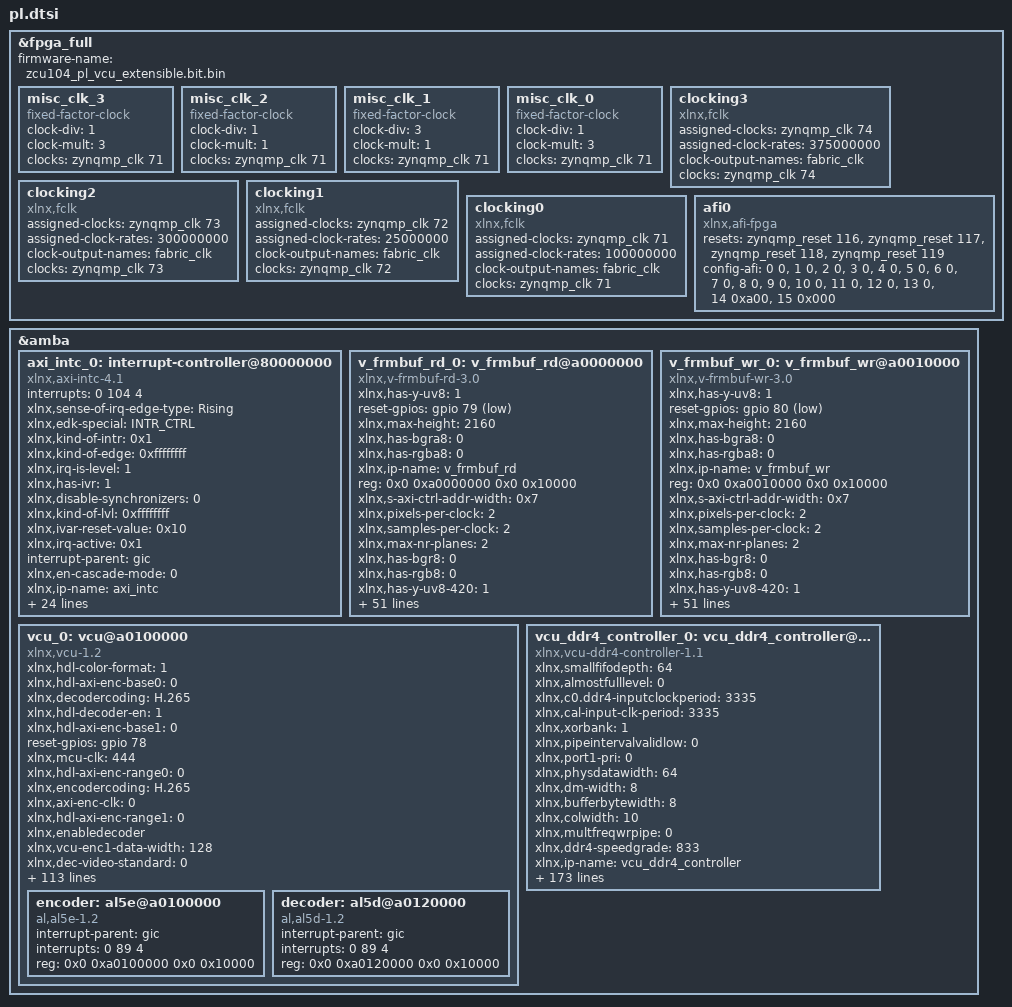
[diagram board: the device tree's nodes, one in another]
/dts-v1/;
/plugin/;
&fpga_full {
	firmware-name = "zcu104_pl_vcu_extensible.bit.bin";
	misc_clk_3: misc_clk_3 {
		clock-div = <1>;
		compatible = "fixed-factor-clock";
		clock-mult = <3>;
		clocks = <&zynqmp_clk 71>;
		#clock-cells = <0>;
	};
	misc_clk_2: misc_clk_2 {
		clock-div = <1>;
		compatible = "fixed-factor-clock";
		clock-mult = <1>;
		clocks = <&zynqmp_clk 71>;
		#clock-cells = <0>;
	};
	misc_clk_1: misc_clk_1 {
		clock-div = <3>;
		compatible = "fixed-factor-clock";
		clock-mult = <1>;
		clocks = <&zynqmp_clk 71>;
		#clock-cells = <0>;
	};
	misc_clk_0: misc_clk_0 {
		clock-div = <1>;
		compatible = "fixed-factor-clock";
		clock-mult = <3>;
		clocks = <&zynqmp_clk 71>;
		#clock-cells = <0>;
	};
	clocking3: clocking3 {
		compatible = "xlnx,fclk";
		assigned-clocks = <&zynqmp_clk 74>;
		assigned-clock-rates = <375000000>;
		#clock-cells = <0>;
		clock-output-names = "fabric_clk";
		clocks = <&zynqmp_clk 74>;
	};
	clocking2: clocking2 {
		compatible = "xlnx,fclk";
		assigned-clocks = <&zynqmp_clk 73>;
		assigned-clock-rates = <300000000>;
		#clock-cells = <0>;
		clock-output-names = "fabric_clk";
		clocks = <&zynqmp_clk 73>;
	};
	clocking1: clocking1 {
		compatible = "xlnx,fclk";
		assigned-clocks = <&zynqmp_clk 72>;
		assigned-clock-rates = <25000000>;
		#clock-cells = <0>;
		clock-output-names = "fabric_clk";
		clocks = <&zynqmp_clk 72>;
	};
	clocking0: clocking0 {
		compatible = "xlnx,fclk";
		assigned-clocks = <&zynqmp_clk 71>;
		assigned-clock-rates = <100000000>;
		#clock-cells = <0>;
		clock-output-names = "fabric_clk";
		clocks = <&zynqmp_clk 71>;
	};
	afi0: afi0 {
		compatible = "xlnx,afi-fpga";
		resets = <&zynqmp_reset 116>, <&zynqmp_reset 117>, <&zynqmp_reset 118>, <&zynqmp_reset 119>;
		config-afi = < 0 0>, <1 0>, <2 0>, <3 0>, <4 0>, <5 0>, <6 0>, <7 0>, <8 0>, <9 0>, <10 0>, <11 0>, <12 0>, <13 0>, <14 0xa00>, <15 0x000>;
	};
};

&amba {
	axi_intc_0: interrupt-controller@80000000 {
		#interrupt-cells = <2>;
		interrupts = < 0 104 4 >;
		xlnx,sense-of-irq-edge-type = "Rising";
		xlnx,edk-special = "INTR_CTRL";
		xlnx,kind-of-intr = <0x1>;
		xlnx,kind-of-edge = <0xffffffff>;
		xlnx,irq-is-level = <1>;
		xlnx,has-ivr = <1>;
		compatible = "xlnx,axi-intc-4.1" , "xlnx,xps-intc-1.00.a";
		xlnx,disable-synchronizers = <0>;
		xlnx,kind-of-lvl = <0xffffffff>;
		xlnx,ivar-reset-value = <0x10>;
		xlnx,irq-active = <0x1>;
		interrupt-parent = <&gic>;
		xlnx,en-cascade-mode = <0>;
		xlnx,ip-name = "axi_intc";
		xlnx,has-ilr = <0>;
		reg = <0x0 0x80000000 0x0 0x10000>;
		xlnx,addr-width = <0x20>;
		clocks = <&zynqmp_clk 71>;
		xlnx,s-axi-aclk-freq-mhz = <100>;
		xlnx,num-sw-intr = <0>;
		xlnx,irq-connection = <1>;
		xlnx,num-intr-inputs = <0x1>;
		xlnx,has-sie = <1>;
		xlnx,enable-async = <0>;
		xlnx,has-cie = <1>;
		xlnx,num-sync-ff = <2>;
		xlnx,edk-iptype = "PERIPHERAL";
		xlnx,mb-clk-not-connected = <1>;
		xlnx,has-ipr = <1>;
		xlnx,sense-of-irq-level-type = "Active_High";
		xlnx,cascade-master = <0>;
		xlnx,processor-clk-freq-mhz = <100>;
		xlnx,is-fast = <0x0>;
		clock-names = "s_axi_aclk";
		xlnx,has-fast = <0>;
		xlnx,ivar-rst-val = <0x10>;
		interrupt-controller;
		interrupt-names = "irq";
		xlnx,async-intr = <0xffffffff>;
		xlnx,name = "axi_intc_0";
	};
	v_frmbuf_rd_0: v_frmbuf_rd@a0000000 {
		xlnx,has-y-uv8 = <1>;
		reset-gpios = <&gpio 79 1>;
		xlnx,max-height = <2160>;
		xlnx,has-bgra8 = <0>;
		xlnx,has-rgba8 = <0>;
		xlnx,ip-name = "v_frmbuf_rd";
		reg = <0x0 0xa0000000 0x0 0x10000>;
		xlnx,s-axi-ctrl-addr-width = <0x7>;
		xlnx,pixels-per-clock = <2>;
		xlnx,samples-per-clock = <2>;
		xlnx,max-nr-planes = <2>;
		xlnx,has-bgr8 = <0>;
		xlnx,has-rgb8 = <0>;
		xlnx,has-y-uv8-420 = <1>;
		xlnx,has-yuyv8 = <0>;
		xlnx,has-y-u-v8 = <0>;
		interrupt-names = "interrupt";
		compatible = "xlnx,v-frmbuf-rd-3.0" , "xlnx,axi-frmbuf-rd-v2.2";
		xlnx,max-width = <3840>;
		xlnx,has-rgb16 = <0>;
		xlnx,vid-formats = "y8" , "y10" , "nv12" , "nv16" , "xv20" , "xv15";
		xlnx,has-bgrx8 = <0>;
		xlnx,has-rgbx8 = <0>;
		xlnx,has-rgbx10 = <0>;
		interrupt-parent = <&gic>;
		xlnx,aximm-num-outstanding = <4>;
		xlnx,has-uyvy8 = <0>;
		xlnx,use-uram = <0>;
		xlnx,has-rgbx12 = <0>;
		xlnx,aximm-burst-length = <16>;
		xlnx,aximm-addr-width = <64>;
		xlnx,video-width = <10>;
		xlnx,max-cols = <3840>;
		xlnx,has-yuv8 = <0>;
		xlnx,has-y-uv10-420 = <1>;
		xlnx,has-yuva8 = <0>;
		xlnx,has-y-uv12-420 = <0>;
		xlnx,name = "v_frmbuf_rd_0";
		interrupts = < 0 90 4 >;
		xlnx,has-y10 = <1>;
		xlnx,has-y-uv16-420 = <0>;
		xlnx,has-y12 = <0>;
		xlnx,has-alpha = <0>;
		xlnx,has-y-u-v10 = <0>;
		clocks = <&misc_clk_0>;
		xlnx,has-y16 = <0>;
		xlnx,dma-align = <16>;
		xlnx,has-y-u-v12 = <0>;
		xlnx,edk-iptype = "PERIPHERAL";
		xlnx,has-interlaced = <0>;
		xlnx,has-yuv16 = <0>;
		xlnx,has-yuvx8 = <0>;
		xlnx,is-tile-format = <0>;
		xlnx,dma-addr-width = <64>;
		clock-names = "ap_clk";
		xlnx,s-axi-ctrl-data-width = <0x20>;
		xlnx,has-y8 = <1>;
		xlnx,has-y-uv10 = <1>;
		xlnx,has-y-uv12 = <0>;
		xlnx,max-rows = <2160>;
		xlnx,has-yuvx10 = <0>;
		#dma-cells = <1>;
		xlnx,has-yuvx12 = <0>;
		xlnx,has-y-uv16 = <0>;
		xlnx,max-data-width = <10>;
		xlnx,has-y-u-v8-420 = <0>;
		xlnx,num-video-components = <3>;
		xlnx,aximm-data-width = <128>;
	};
	v_frmbuf_wr_0: v_frmbuf_wr@a0010000 {
		xlnx,has-y-uv8 = <1>;
		reset-gpios = <&gpio 80 1>;
		xlnx,max-height = <2160>;
		xlnx,has-bgra8 = <0>;
		xlnx,has-rgba8 = <0>;
		xlnx,ip-name = "v_frmbuf_wr";
		reg = <0x0 0xa0010000 0x0 0x10000>;
		xlnx,s-axi-ctrl-addr-width = <0x7>;
		xlnx,pixels-per-clock = <2>;
		xlnx,samples-per-clock = <2>;
		xlnx,max-nr-planes = <2>;
		xlnx,has-bgr8 = <0>;
		xlnx,has-rgb8 = <0>;
		xlnx,has-y-uv8-420 = <1>;
		xlnx,has-yuyv8 = <0>;
		xlnx,has-y-u-v8 = <0>;
		interrupt-names = "interrupt";
		compatible = "xlnx,v-frmbuf-wr-3.0" , "xlnx,axi-frmbuf-wr-v2.2";
		xlnx,max-width = <3840>;
		xlnx,has-rgb16 = <0>;
		xlnx,vid-formats = "y8" , "y10" , "nv12" , "nv16" , "xv20" , "xv15";
		xlnx,has-bgrx8 = <0>;
		xlnx,has-rgbx8 = <0>;
		xlnx,has-rgbx10 = <0>;
		interrupt-parent = <&gic>;
		xlnx,aximm-num-outstanding = <4>;
		xlnx,has-uyvy8 = <0>;
		xlnx,use-uram = <0>;
		xlnx,has-rgbx12 = <0>;
		xlnx,aximm-burst-length = <16>;
		xlnx,aximm-addr-width = <32>;
		xlnx,video-width = <10>;
		xlnx,max-cols = <3840>;
		xlnx,has-yuv8 = <0>;
		xlnx,has-y-uv10-420 = <1>;
		xlnx,has-yuva8 = <0>;
		xlnx,has-y-uv12-420 = <0>;
		xlnx,name = "v_frmbuf_wr_0";
		interrupts = < 0 91 4 >;
		xlnx,has-y10 = <1>;
		xlnx,has-y-uv16-420 = <0>;
		xlnx,has-y12 = <0>;
		xlnx,has-alpha = <0>;
		xlnx,has-y-u-v10 = <0>;
		clocks = <&misc_clk_0>;
		xlnx,has-y16 = <0>;
		xlnx,dma-align = <16>;
		xlnx,has-y-u-v12 = <0>;
		xlnx,edk-iptype = "PERIPHERAL";
		xlnx,has-interlaced = <0>;
		xlnx,has-yuv16 = <0>;
		xlnx,has-yuvx8 = <0>;
		xlnx,is-tile-format = <0>;
		xlnx,dma-addr-width = <32>;
		clock-names = "ap_clk";
		xlnx,s-axi-ctrl-data-width = <0x20>;
		xlnx,has-y8 = <1>;
		xlnx,has-y-uv10 = <1>;
		xlnx,has-y-uv12 = <0>;
		xlnx,max-rows = <2160>;
		xlnx,has-yuvx10 = <0>;
		#dma-cells = <1>;
		xlnx,has-yuvx12 = <0>;
		xlnx,has-y-uv16 = <0>;
		xlnx,max-data-width = <10>;
		xlnx,has-y-u-v8-420 = <0>;
		xlnx,num-video-components = <3>;
		xlnx,aximm-data-width = <128>;
	};
	vcu_0: vcu@a0100000 {
		xlnx,hdl-color-format = <1>;
		xlnx,hdl-axi-enc-base0 = <0>;
		xlnx,decodercoding = "H.265";
		xlnx,hdl-decoder-en = <1>;
		xlnx,hdl-axi-enc-base1 = <0>;
		reset-gpios = <&gpio 78 0>;
		xlnx,mcu-clk = <444>;
		xlnx,hdl-axi-enc-range0 = <0>;
		xlnx,encodercoding = "H.265";
		xlnx,axi-enc-clk = <0>;
		xlnx,hdl-axi-enc-range1 = <0>;
		xlnx,enabledecoder;
		xlnx,vcu-enc1-data-width = <128>;
		xlnx,dec-video-standard = <0>;
		xlnx,pll-bypass = <0>;
		xlnx,hdl-dec-fps = <60>;
		xlnx,encverresolution = <2160>;
		xlnx,enc-mem-bram-used = <0>;
		xlnx,ip-name = "vcu";
		#size-cells = <2>;
		reg = <0x0 0xa0140000 0x0 0x1000>, <0x0 0xa0141000 0x0 0x1000>;
		xlnx,hdl-enc-clk = <0>;
		xlnx,hdl-enc-buffer-en = <1>;
		#address-cells = <2>;
		xlnx,hdl-axi-mcu-range = <0>;
		xlnx,vcu-dec0-data-width = <128>;
		xlnx,enc-fps = <1>;
		xlnx,dec-coding-type = <1>;
		xlnx,axi-enc-range0 = <0>;
		interrupt-names = "vcu_host_interrupt";
		xlnx,hdl-vcu-test-en = <0>;
		xlnx,hdl-coding-type = <1>;
		xlnx,enc-color-format = <1>;
		xlnx,axi-enc-range1 = <0>;
		xlnx,decoderchromaformat = "4_2_2";
		compatible = "xlnx,vcu-1.2" , "xlnx,vcu";
		xlnx,vcu-axiliteapb-data-width = <32>;
		xlnx,dec-color-depth = <1>;
		xlnx,enable-encoder;
		xlnx,hdl-encoder-en = <1>;
		xlnx,decverresolution = <2160>;
		interrupt-parent = <&gic>;
		xlnx,hdl-dec-frame-size-x = <3840>;
		xlnx,hdl-color-depth = <1>;
		xlnx,hdl-dec-frame-size-y = <2160>;
		xlnx,hdl-axi-mcu-clk = <1079194419>;
		xlnx,enc-video-standard = <0>;
		ranges;
		xlnx,enc-mem-uram-used = <1710>;
		xlnx,decodernumcores = <2>;
		xlnx,no-of-streams = <8>;
		xlnx,hdl-dec-video-standard = <0>;
		xlnx,axi-mcu-clk = <330>;
		xlnx,hdl-pll-bypass = <0>;
		xlnx,enc-buffer-manual-override = <0>;
		xlnx,dec-color-format = <1>;
		xlnx,pll-clk = <0x1fca055>;
		xlnx,hdl-test-port-en = <0>;
		xlnx,hdl-axi-dec-clk = <0>;
		xlnx,hdl-mcu-clk = <444>;
		xlnx,hdl-axi-mcu-base = <0>;
		xlnx,name = "vcu_0";
		interrupts = < 0 89 4 >;
		xlnx,table-no = <1>;
		xlnx,axi-dec-clk = <0>;
		xlnx,hdl-dec-color-format = <1>;
		xlnx,hdl-ram-type = <0>;
		xlnx,hdl-pll-clk-lo = <32>;
		xlnx,enc-buffer-size-actual = <1710>;
		xlnx,vcu-dec1-data-width = <128>;
		xlnx,vcu-mcu-data-width = <32>;
		xlnx,dec-frame-size = <4>;
		xlnx,enc-buffer-size = <1520>;
		xlnx,hdl-table-no = <1>;
		xlnx,enableencoder;
		clocks = <&misc_clk_1>, <&misc_clk_2>, <&vcu_0 0>, <&vcu_0 1>, <&vcu_0 2>, <&vcu_0 3>;
		xlnx,hdl-dec-coding-type = <1>;
		xlnx,hdl-video-standard = <0>;
		xlnx,dec-fps = <3>;
		xlnx,edk-iptype = "PERIPHERAL";
		xlnx,enc-buffer-b-frame = <1>;
		xlnx,enc-clk = <0>;
		xlnx,vcu-enc0-data-width = <128>;
		xlnx,hdl-fps = <30>;
		xlnx,enc-coding-type = <1>;
		clock-names = "pll_ref" , "aclk" , "vcu_core_enc" , "vcu_mcu_enc" , "vcu_core_dec" , "vcu_mcu_dec";
		xlnx,hdl-dec-color-depth = <1>;
		xlnx,hdl-enc-buffer-motion-vec-range = <0>;
		xlnx,hdl-enc-buffer-manual-override = <0>;
		xlnx,hdl-axi-dec-range0 = <0>;
		xlnx,enable-decoder;
		xlnx,hdl-axi-dec-range1 = <0>;
		xlnx,encoderchromaformat = "4_2_2";
		xlnx,enchorresolution = <3840>;
		xlnx,axi-dec-base0 = <0>;
		xlnx,no-of-dec-streams = <1>;
		xlnx,hdl-wpp-en = <0>;
		xlnx,enc-color-depth = <1>;
		xlnx,enc-buffer-type = <0>;
		xlnx,axi-dec-base1 = <0>;
		xlnx,decodercodingtype = "INTRA_ONLY";
		xlnx,hdl-frame-size-x = <1920>;
		xlnx,axi-enc-base0 = <0>;
		xlnx,enc-buffer-motion-vec-range = <0>;
		xlnx,hdl-frame-size-y = <1080>;
		xlnx,encodercodingtype = "INTRA_ONLY";
		xlnx,enc-frame-size = <3>;
		xlnx,axi-enc-base1 = <0>;
		xlnx,core-clk = <667>;
		xlnx,hdl-num-concurrent-streams = <4>;
		xlnx,hdl-pll-clk-hi = <33>;
		xlnx,decodercolordepth = <10>;
		xlnx,encodernumcores = <4>;
		xlnx,encodercolordepth = <10>;
		xlnx,axi-mcu-base = <0>;
		xlnx,hdl-core-clk = <667>;
		xlnx,axi-dec-range0 = <0>;
		xlnx,enc-buffer-en;
		xlnx,hdl-mem-depth = <38912>;
		xlnx,axi-dec-range1 = <0>;
		xlnx,axi-mcu-range = <0>;
		xlnx,wpp-en = <0>;
		xlnx,hdl-axi-dec-base0 = <0>;
		reg-names = "vcu_slcr" , "logicore";
		#clock-cells = <1>;
		xlnx,mcu-debug = <0>;
		xlnx,hdl-num-streams = <8>;
		xlnx,hdl-max-num-cores = <4>;
		xlnx,hdl-enc-buffer-b-frame = <1>;
		xlnx,hdl-axi-enc-clk = <0>;
		xlnx,hdl-axi-dec-base1 = <0>;
		xlnx,coreclkfreq = <667>;
		xlnx,dechorresolution = <3840>;
		encoder: al5e@a0100000 {
			interrupt-parent = <&gic>;
			interrupts = < 0 89 4 >;
			compatible = "al,al5e-1.2" , "al,al5e";
			reg = <0x0 0xa0100000 0x0 0x10000>;
		};
		decoder: al5d@a0120000 {
			interrupt-parent = <&gic>;
			interrupts = < 0 89 4 >;
			compatible = "al,al5d-1.2" , "al,al5d";
			reg = <0x0 0xa0120000 0x0 0x10000>;
		};
	};
	vcu_ddr4_controller_0: vcu_ddr4_controller@4800000000 {
		xlnx,smallfifodepth = <64>;
		xlnx,almostfulllevel = <0>;
		xlnx,c0.ddr4-inputclockperiod = <3335>;
		xlnx,cal-input-clk-period = <3335>;
		xlnx,xorbank = <1>;
		xlnx,pipeintervalvalidlow = <0>;
		xlnx,port1-pri = <0>;
		xlnx,physdatawidth = <64>;
		xlnx,dm-width = <8>;
		xlnx,bufferbytewidth = <8>;
		xlnx,colwidth = <10>;
		xlnx,multfreqwrpipe = <0>;
		xlnx,ddr4-speedgrade = <833>;
		xlnx,ip-name = "vcu_ddr4_controller";
		xlnx,port3-pri = <1>;
		xlnx,pipeintervalwaithigh = <3>;
		xlnx,ddr4-custompartsfile = "no_file_loaded";
		reg = <0x00000048 0x00000000 0x0 0x80000000>;
		xlnx,usrwrpipe = <1>;
		xlnx,nbseq = <1>;
		xlnx,logenable = <0>;
		xlnx,data-buf-addr-width = <5>;
		xlnx,cust-ddr4-timeperiod = <833>;
		xlnx,hdl-port0-en = <1>;
		xlnx,dualclock = <0>;
		xlnx,ddr4-cmdgetaddr = <22>;
		xlnx,writedelay = <7>;
		xlnx,burstlength = <8>;
		xlnx,nbchipselect = <1>;
		xlnx,iaddrwidth = <22>;
		xlnx,bankwidth = <4>;
		xlnx,bufferdatawidth = <128>;
		xlnx,clkout1-divide-mmcm = <6>;
		xlnx,nbfifo = <16>;
		xlnx,odtend = <6>;
		xlnx,nrtr = <13>;
		xlnx,dram-width-hdl = <0>;
		xlnx,divclk-divide-mmcm = <3>;
		xlnx,cust-csv-memtype = "Components";
		xlnx,ddr4-cust-file-en = <0>;
		xlnx,data-width = <0>;
		xlnx,cwlatency = <14>;
		compatible = "xlnx,vcu-ddr4-controller-1.1";
		xlnx,c0-ddr4-divclk-divide = <3>;
		xlnx,nrtw = <3>;
		xlnx,cmdrep = <0>;
		xlnx,speed-bin-hdl = <1>;
		xlnx,areset = <0>;
		xlnx,c0-ddr4-clkfbout-mult = <16>;
		xlnx,nodatacmdslot = <3>;
		xlnx,hdl-port3-en = <1>;
		xlnx,dimm-value-hdl = <0>;
		xlnx,ddr4-sdrambank = <16>;
		xlnx,trfc = <260>;
		xlnx,physaddrwidth = <17>;
		xlnx,wrpipe = <1>;
		xlnx,caslatency = <15>;
		xlnx,c0.ddr4-clkout0-divide = <6>;
		xlnx,drivestrength = <0>;
		xlnx,ddr4-cmdflag = <16>;
		xlnx,rddatafifopipe = <1>;
		xlnx,resetlevel = <1>;
		xlnx,ref-clk = <300>;
		xlnx,nfaw = <6>;
		xlnx,maxpostedrefresh = <1>;
		xlnx,ddr4-cmdwait = <16>;
		xlnx,cust-csv-clkout2-freq = <300>;
		xlnx,twr = <15>;
		xlnx,coldelay = <4>;
		xlnx,writegrouping = <32>;
		xlnx,c0.ddr4-timeperiod = <938>;
		xlnx,port0-pri-idx = <1>;
		xlnx,dbgmoncntsize = <16>;
		xlnx,c0.controllertype = "ddr4_sdram";
		xlnx,combineaxiburst = <1>;
		xlnx,rowwidth = <15>;
		xlnx,port1-pri-idx = <2>;
		xlnx,port2-pri-idx = <4>;
		xlnx,enable-port0;
		xlnx,name = "vcu_ddr4_controller_0";
		xlnx,usrburstwidth = <8>;
		xlnx,tck = <938>;
		xlnx,port3-pri-idx = <5>;
		xlnx,enable-port1;
		xlnx,ddr = <4>;
		xlnx,port4-pri-idx = <3>;
		xlnx,nwtr = <7>;
		xlnx,no-of-axi-ports = <5>;
		xlnx,nbcke = <1>;
		xlnx,hdl-port1-en = <1>;
		xlnx,enable-port2;
		xlnx,cust-enable = <0>;
		xlnx,c0.ddr4-divclk-divide = <3>;
		xlnx,incrburst = <0>;
		xlnx,fastfaw = <0>;
		xlnx,enable-port3;
		xlnx,nbbank = <16>;
		xlnx,port0-pri = <0>;
		xlnx,enable-port4;
		xlnx,dqs-width = <8>;
		xlnx,c0.ddr4-clkfbout-mult = <16>;
		xlnx,trace-length = <3>;
		xlnx,clkinperiodmmcm = <3335>;
		xlnx,readgrouping = <96>;
		xlnx,port2-pri = <1>;
		xlnx,ping-pong = <1>;
		xlnx,cust-csv-datawidth = <64>;
		xlnx,nwtw = <16>;
		xlnx,multfreq = <1>;
		xlnx,memory-timeperiod = <100>;
		xlnx,dram-speed-bin = <2>;
		xlnx,ddr4-customparts = "no_file_loaded";
		clocks = <&misc_clk_3>;
		xlnx,regcmdaddrincr = <0>;
		xlnx,port4-pri = <0>;
		xlnx,addrpipe = <0>;
		xlnx,nbhiprior-ports = <3>;
		xlnx,pipeintervalvalidhigh = <3>;
		xlnx,addrwidth = <26>;
		xlnx,ck-width = <1>;
		xlnx,clkout0-divide-mmcm = <6>;
		xlnx,edk-iptype = "PERIPHERAL";
		xlnx,perrd = <1>;
		xlnx,addn-ui-clkout2-freq-hz = <267>;
		xlnx,clkout2-divide-mmcm = <6>;
		xlnx,hdl-port4-en = <1>;
		xlnx,fifo-depth = <256>;
		xlnx,ddr4-cmdstrobe = <16>;
		xlnx,bg-width = <1>;
		xlnx,c0-controllertype = <0>;
		xlnx,choose-ram = <0>;
		xlnx,clkfboutmultmmcm = <16>;
		xlnx,nrrd = <1>;
		clock-names = "S_Axi_Clk";
		xlnx,trpa = <14998>;
		xlnx,nzqcs = <64>;
		xlnx,maddrwidth = <26>;
		xlnx,ddr4-cmdtoken = <16>;
		xlnx,wrpipebram = <1>;
		xlnx,replicatefract = <1>;
		xlnx,dram-width = <0>;
		xlnx,ddr4-tck-op = <750>;
		xlnx,trefi = <7800>;
		xlnx,ref-clk-var = <3335>;
		xlnx,enable-decoder;
		xlnx,axi-addrwidth = <32>;
		xlnx,waitfast = <0>;
		xlnx,maxdatasize = <2048>;
		xlnx,ddraxiburstratio = <2>;
		xlnx,wr-port0-pri-idx = <1>;
		xlnx,odtstart = <4>;
		xlnx,wr-port1-pri-idx = <2>;
		xlnx,tzqcsi = <256>;
		xlnx,rdpipebram = <0>;
		xlnx,part-sg = <2>;
		xlnx,mc-bg = <15>;
		xlnx,nrrd-s = <0>;
		xlnx,clkout2-divide = <6>;
		xlnx,wr-port2-pri-idx = <3>;
		xlnx,chipgrouping = <4>;
		xlnx,wrack = <1>;
		xlnx,wr-port3-pri-idx = <4>;
		xlnx,is-cke-shared = <0>;
		xlnx,active-axi-ports = <5>;
		xlnx,wr-port4-pri-idx = <5>;
		xlnx,ddr4-op-clk = <300>;
		xlnx,csv-file-en = <0>;
		xlnx,bankgroupwidth = <2>;
		xlnx,compbits = <10000>;
		xlnx,pipeintervalwaitlow = <0>;
		xlnx,gui-csv-ddr4-custompartsfile = "no_file_loaded";
		xlnx,gui-csv-ddr4-customparts = "no_file_loaded";
		xlnx,ddr4-inputclk-period-ip = <2500>;
		xlnx,usrflag = <16>;
		xlnx,rdpipe = <0>;
		xlnx,odt-width = <1>;
		xlnx,norefresh = <0>;
		xlnx,hdl-port2-en = <1>;
		xlnx,hdl-nobuffer = <0>;
		xlnx,dqwidth = <64>;
		xlnx,cust-csv-partname = "MT40A1G8SA-075:E";
		xlnx,op-clk = <300>;
		xlnx,dimm-type = <0>;
		xlnx,nck-per-clk = <4>;
		xlnx,m-addn-ui-clkout2-freq-hz = <0>;
		xlnx,ddr4-cmdindex = <128>;
		xlnx,c0-ddr4-clkout0-divide = <6>;
		xlnx,initbyphy = <1>;
	};
};
